AUTOSAR XML (schema 4-2-2)
package /ComponentTypes
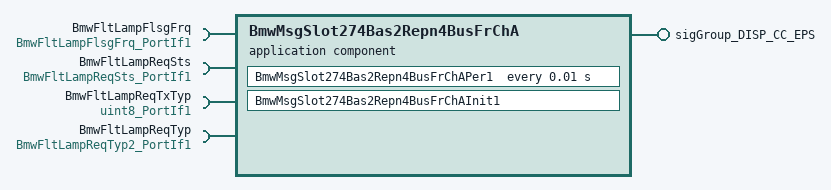
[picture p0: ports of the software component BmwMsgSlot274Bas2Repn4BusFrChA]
  application sw component type BmwMsgSlot274Bas2Repn4BusFrChA
    provide port sigGroup_DISP_CC_EPS: nonqueued-sender-com-spec{data-element=sigGroup_DISP_CC_EPS, uses-end-to-end-protection=true, init-value=fields=[ST_CC_EPS:0, ALIV_DISP_CC_EPS:15, ST_IDC_CC_EPS:0, CRC_DISP_CC_EPS:0, CHL_DISP_CC_EPS:12, NO_CC_EPS:65534, TRANF_CC_EPS:5]}, provided-interface=sigGroup_DISP_CC_EPS
    4 x require port:
      BmwFltLampFlsgFrq: nonqueued-receiver-com-spec{data-element=Val, filter=data-filter-type=ALWAYS, init-value=0}, required-interface=BmwFltLampFlsgFrq_PortIf1
      BmwFltLampReqSts: nonqueued-receiver-com-spec{data-element=Val, filter=data-filter-type=ALWAYS, init-value=0}, required-interface=BmwFltLampReqSts_PortIf1
      BmwFltLampReqTxTyp: nonqueued-receiver-com-spec{data-element=Val, filter=data-filter-type=ALWAYS, init-value=5}, required-interface=uint8_PortIf1
      BmwFltLampReqTyp: nonqueued-receiver-com-spec{data-element=Val, filter=data-filter-type=ALWAYS, init-value=0}, required-interface=BmwFltLampReqTyp2_PortIf1
    behavior BmwMsgSlot274Bas2Repn4BusFrChA_InternalBehavior
      ar-typed-per-instance-memorys:
        6 x data, all with sw-calibration-access=READ-ONLY:
          BmwFltLampFlsgFrqPrev: type=BmwFltLampFlsgFrq1
          BmwFltLampReqStsPrev: type=BmwFltLampReqSts1
          BmwFltLampReqTxTypPrev: type=uint8
          BmwFltLampReqTypPrev: type=BmwFltLampReqTyp2
          LstTxCntr: type=uint8
          PerdCntr: type=uint8
      init event BmwMsgSlot274Bas2Repn4BusFrChA_InitEvent: start-on-event=BmwMsgSlot274Bas2Repn4BusFrChAInit1
      timing event TMT_BmwMsgSlot274Bas2Repn4BusFrChAPer1: start-on-event=BmwMsgSlot274Bas2Repn4BusFrChAPer1, period=0.01
      port-api-options:
        enable-take-address=false, error-handling=NO-TRANSFORMER-ERROR-HANDLING, indirect-api=false, port=BmwFltLampFlsgFrq
        enable-take-address=false, error-handling=NO-TRANSFORMER-ERROR-HANDLING, indirect-api=false, port=BmwFltLampReqSts
        enable-take-address=false, error-handling=NO-TRANSFORMER-ERROR-HANDLING, indirect-api=false, port=BmwFltLampReqTxTyp
        enable-take-address=false, error-handling=NO-TRANSFORMER-ERROR-HANDLING, indirect-api=false, port=BmwFltLampReqTyp
        enable-take-address=false, error-handling=NO-TRANSFORMER-ERROR-HANDLING, indirect-api=false, port=sigGroup_DISP_CC_EPS
      runnable BmwMsgSlot274Bas2Repn4BusFrChAInit1
      runnable BmwMsgSlot274Bas2Repn4BusFrChAPer1
        data-receive-point-by-arguments:
          4 x access:
            REC_BmwFltLampFlsgFrq_Val: accessed-variable=BmwFltLampFlsgFrq.Val
            REC_BmwFltLampReqSts_Val: accessed-variable=BmwFltLampReqSts.Val
            REC_BmwFltLampReqTxTyp_Val: accessed-variable=BmwFltLampReqTxTyp.Val
            REC_BmwFltLampReqTyp_Val: accessed-variable=BmwFltLampReqTyp.Val
        data-send-points:
          access SEND_sigGroup_DISP_CC_EPS_sigGroup_DISP_CC_EPS: accessed-variable=sigGroup_DISP_CC_EPS.sigGroup_DISP_CC_EPS
  swc implementation BmwMsgSlot274Bas2Repn4BusFrChA_Implementation: behavior=BmwMsgSlot274Bas2Repn4BusFrChA_InternalBehavior
    code-descriptors:
      code Default: artifact-descriptors=autosar-engineering-object={short-label=Default, category=SWSRC}
